# IMC300A register map
Vendor: Infineon; File version: 1.0.0
CPU: CM0 r0p0, little endian, no MPU, no FPU, 2 interrupt priority bits
Registers are 32-bit, read-write, reset 0x0 unless marked. A register's access mark holds for its fields unless they carry their own. Offsets are from the block's base; [hi:lo] are bit positions; {n}, {i} and the like mark numbered series; 'fields as' and 'values as' point back to an identical list.

## PORT2
Base 0x40040200
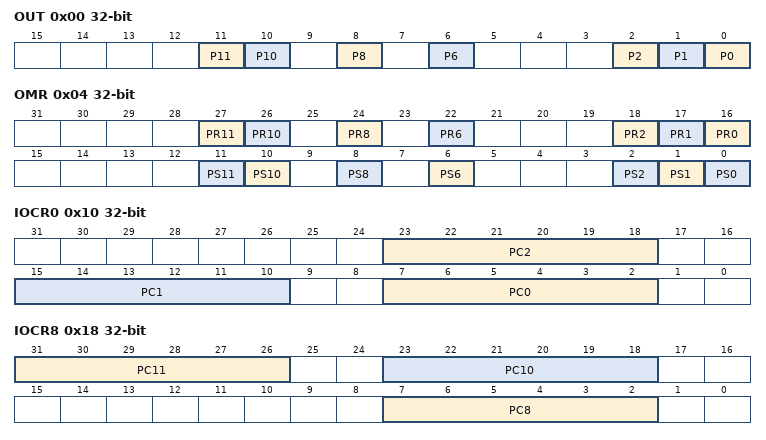
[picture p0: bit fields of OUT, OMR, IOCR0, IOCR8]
0x00 OUT — Port 2 Output Register
  [all] fields
    0=The output level of P2.x is 0; 1=The output level of P2.x is 1
  [11] P11 — Port 2 Output Bit 11
  [10] P10 — Port 2 Output Bit 10
  [8] P8 — Port 2 Output Bit 8
  [6] P6 — Port 2 Output Bit 6
  [2] P2 — Port 2 Output Bit 2
  [1] P1 — Port 2 Output Bit 1
  [0] P0 — Port 2 Output Bit 0
0x04 OMR wo — Port 2 Output Modification Register
  [27] PR11 — Port 2 Reset Bit 11
  [26] PR10 — Port 2 Reset Bit 10
  [24] PR8 — Port 2 Reset Bit 8
  [22] PR6 — Port 2 Reset Bit 6
  [18] PR2 — Port 2 Reset Bit 2
  [17] PR1 — Port 2 Reset Bit 1
  [16] PR0 — Port 2 Reset Bit 0
  [11] PS11 — Port 2 Set Bit 11
  [10] PS10 — Port 2 Set Bit 10
  [8] PS8 — Port 2 Set Bit 8
  [6] PS6 — Port 2 Set Bit 6
  [2] PS2 — Port 2 Set Bit 2
  [1] PS1 — Port 2 Set Bit 1
  [0] PS0 — Port 2 Set Bit 0
0x10 IOCR0 — Port 2 Input/Output Control Register 0
  [23:18] PC2 — Port Control for Port 2 Pin 2
    0=Input - No internal pull device active; 1=Input - Internal pull-down device active; 2=Input - Internal pull-up device active; 3=Input - No internal pull device, Pn_OUTx = input value; 4=Input inverted - No internal pull device active; 5=Input inverted - Internal pull-down device active; 6=Input inverted - Internal pull-up device active; 7=Input inverted - No internal pull device, Pn_OUTx = input value
  [15:10] PC1 — Port Control for Port 2 Pin 1
    0=Input - No internal pull device active; 1=Input - Internal pull-down device active; 2=Input - Internal pull-up device active; 3=Input - No internal pull device, Pn_OUTx = input value; 4=Input inverted - No internal pull device active; 5=Input inverted - Internal pull-down device active; 6=Input inverted - Internal pull-up device active; 7=Input inverted - No internal pull device, Pn_OUTx = input value; 32=Output Push-Pull - General-purpose output; {v}=Output Push-Pull - Alternate output function {v-32} (v=33..41); 48=Output Open Drain - General-purpose output; {v}=Output Open Drain - Alternate output function {v-48} (v=49..57)
  [7:2] PC0 — Port Control for Port 2 Pin 0
    values as PC1
0x14 IOCR4 — Port 2 Input/Output Control Register 4
  [23:18] PC6 — Port Control for Port 2 Pin 6
    values as IOCR0.PC2
0x18 IOCR8 — Port 2 Input/Output Control Register 8
  [31:26] PC11 — Port Control for Port 2 Pin 11
    values as IOCR0.PC1
  [23:18] PC10 — Port Control for Port 2 Pin 10
    values as IOCR0.PC1
  [7:2] PC8 — Port Control for Port 2 Pin 8
    values as IOCR0.PC2
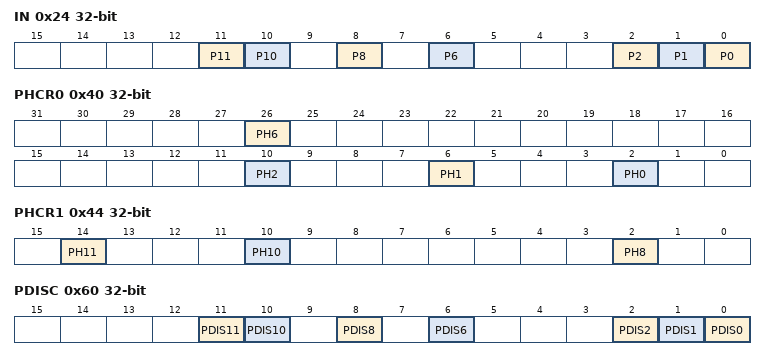
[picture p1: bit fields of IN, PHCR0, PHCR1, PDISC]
0x24 IN ro (reset mask 0xFFFF0000) — Port 2 Input Register
  [11] P11 — Port 2 Input Bit 11
    0=The input level of P2.11 is 0; 1=The input level of P2.11 is 1
  [10] P10 — Port 2 Input Bit 10
    0=The input level of P2.10 is 0; 1=The input level of P2.10 is 1
  [8] P8 — Port 2 Input Bit 8
    0=The input level of P2.8 is 0; 1=The input level of P2.8 is 1
  [6] P6 — Port 2 Input Bit 6
    0=The input level of P2.6 is 0; 1=The input level of P2.6 is 1
  [2] P2 — Port 2 Input Bit 2
    0=The input level of P2.2 is 0; 1=The input level of P2.2 is 1
  [1] P1 — Port 2 Input Bit 1
    0=The input level of P2.1 is 0; 1=The input level of P2.1 is 1
  [0] P0 — Port 2 Input Bit 0
    0=The input level of P2.0 is 0; 1=The input level of P2.0 is 1
0x40 PHCR0 — Port 2 Pad Hysteresis Control Register 0
  [26] PH6 — Pad Hysteresis for P2.6
  [10] PH2 — Pad Hysteresis for P2.2
  [6] PH1 — Pad Hysteresis for P2.1
  [2] PH0 — Pad Hysteresis for P2.0
0x44 PHCR1 — Port 2 Pad Hysteresis Control Register 1
  [14] PH11 — Pad Hysteresis for P2.11
  [10] PH10 — Pad Hysteresis for P2.10
  [2] PH8 — Pad Hysteresis for P2.8
0x60 PDISC (reset mask 0xFFFF0000) — Port 2 Pin Function Decision Control Register
  [all] fields
    0=Analog input and digital input/output path active; 1=Analog input path active
  [11] PDIS11 — Pad Disable for Port 2 Pin 11
  [10] PDIS10 — Pad Disable for Port 2 Pin 10
  [8] PDIS8 — Pad Disable for Port 2 Pin 8
  [6] PDIS6 — Pad Disable for Port 2 Pin 6
  [2] PDIS2 — Pad Disable for Port 2 Pin 2
  [1] PDIS1 — Pad Disable for Port 2 Pin 1
  [0] PDIS0 — Pad Disable for Port 2 Pin 0
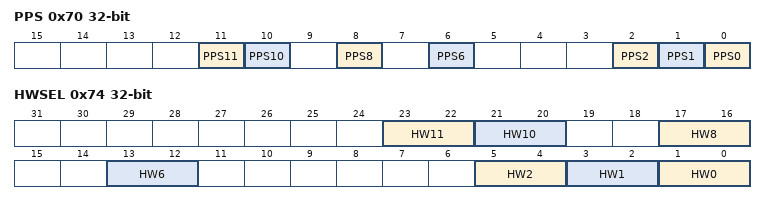
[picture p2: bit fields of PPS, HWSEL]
0x70 PPS — Port 2 Pin Power Save Register
  [11] PPS11 — Port 2 Pin Power Save Bit 11
    0=Pin Power Save of P2.11 is disabled; 1=Pin Power Save of P2.11 is enabled
  [10] PPS10 — Port 2 Pin Power Save Bit 10
    0=Pin Power Save of P2.10 is disabled; 1=Pin Power Save of P2.10 is enabled
  [8] PPS8 — Port 2 Pin Power Save Bit 8
    0=Pin Power Save of P2.8 is disabled; 1=Pin Power Save of P2.8 is enabled
  [6] PPS6 — Port 2 Pin Power Save Bit 6
    0=Pin Power Save of P2.6 is disabled; 1=Pin Power Save of P2.6 is enabled
  [2] PPS2 — Port 2 Pin Power Save Bit 2
    0=Pin Power Save of P2.2 is disabled; 1=Pin Power Save of P2.2 is enabled
  [1] PPS1 — Port 2 Pin Power Save Bit 1
    0=Pin Power Save of P2.1 is disabled; 1=Pin Power Save of P2.1 is enabled
  [0] PPS0 — Port 2 Pin Power Save Bit 0
    0=Pin Power Save of P2.0 is disabled; 1=Pin Power Save of P2.0 is enabled
0x74 HWSEL — Port 2 Pin Hardware Select Register
  [all] fields
    0=Software control only; 1=HW0 control path can override the software configuration; 2=HW1 control path can override the software configuration
  [23:22] HW11 — Port 2 Pin Hardware Select Bit 11
  [21:20] HW10 — Port 2 Pin Hardware Select Bit 10
  [17:16] HW8 — Port 2 Pin Hardware Select Bit 8
  [13:12] HW6 — Port 2 Pin Hardware Select Bit 6
  [5:4] HW2 — Port 2 Pin Hardware Select Bit 2
  [3:2] HW1 — Port 2 Pin Hardware Select Bit 1
  [1:0] HW0 — Port 2 Pin Hardware Select Bit 0
